# lilium_network register map
Vendor: Nordic Semiconductor; Series: nrfXX; File version: 1
CPU: CM33 r0p4, little endian, MPU, no FPU, 3 interrupt priority bits, 30 interrupts
Registers are 32-bit, read-write, reset 0x0 unless marked. A register's access mark holds for its fields unless they carry their own. Offsets are from the block's base; [hi:lo] are bit positions; {n}, {i} and the like mark numbered series; 'fields as' and 'values as' point back to an identical list.

## RADIO (part 1 of 3) — 2.4 GHz radio
Base 0x41008000
0x00 TASKS_TXEN wo — Enable RADIO in TX mode
  [0] TASKS_TXEN
    1=Trigger task
0x04 TASKS_RXEN wo — Enable RADIO in RX mode
  [0] TASKS_RXEN
    1=Trigger task
0x08 TASKS_START wo — Start RADIO
  [0] TASKS_START
    1=Trigger task
0x0C TASKS_STOP wo — Stop RADIO
  [0] TASKS_STOP
    1=Trigger task
0x10 TASKS_DISABLE wo — Disable RADIO
  [0] TASKS_DISABLE
    1=Trigger task
0x14 TASKS_RSSISTART wo — Start the RSSI and take one single sample of the receive signal strength
  [0] TASKS_RSSISTART
    1=Trigger task
0x18 TASKS_BCSTART wo — Start the bit counter
  [0] TASKS_BCSTART
    1=Trigger task
0x1C TASKS_BCSTOP wo — Stop the bit counter
  [0] TASKS_BCSTOP
    1=Trigger task
0x20 TASKS_EDSTART wo — Start the energy detect measurement used in IEEE 802.15.4 mode
  [0] TASKS_EDSTART
    1=Trigger task
0x24 TASKS_EDSTOP wo — Stop the energy detect measurement
  [0] TASKS_EDSTOP
    1=Trigger task
0x28 TASKS_CCASTART wo — Start the clear channel assessment used in IEEE 802.15.4 mode
  [0] TASKS_CCASTART
    1=Trigger task
0x2C TASKS_CCASTOP wo — Stop the clear channel assessment
  [0] TASKS_CCASTOP
    1=Trigger task
0x30 TASKS_DFESTART wo — Start DFE operation
  [0] TASKS_DFESTART
    1=Trigger task
0x34 TASKS_DFESTOP wo — Stop DFE operation
  [0] TASKS_DFESTOP
    1=Trigger task
0x38 TASKS_ACQINJ0DMASTART wo — Start DMA transaction
  [0] TASKS_ACQINJ0DMASTART
    1=Trigger task
0x3C TASKS_ACQINJ0DMASTOP wo — Stop ongoing DMA transaction
  [0] TASKS_ACQINJ0DMASTOP
    1=Trigger task
0x40 TASKS_ACQINJ1DMASTART wo — Start DMA transaction
  [0] TASKS_ACQINJ1DMASTART
    1=Trigger task
0x44 TASKS_ACQINJ1DMASTOP wo — Stop ongoing DMA transaction
  [0] TASKS_ACQINJ1DMASTOP
    1=Trigger task
0x48 TASKS_CNTPSTART wo — Start packet counter
  [0] TASKS_CNTPSTART
    1=Trigger task
0x4C TASKS_CNTPSTOP wo — Stop packet counter
  [0] TASKS_CNTPSTOP
    1=Trigger task
0x50 TASKS_CNTPCLEAR wo — Clear packet counter
  [0] TASKS_CNTPCLEAR
    1=Trigger task
0x54 TASKS_LOOPBACKEN wo — Enable RADIO in LOOPBACK mode
  [0] TASKS_LOOPBACKEN
    1=Trigger task
0x58 TASKS_CALSTART wo — Start calibration
  [0] TASKS_CALSTART
    1=Trigger task
0x5C TASKS_CALSTOP wo — Stop calibration
  [0] TASKS_CALSTOP
    1=Trigger task
0x60 TASKS_PATESTSTART wo — Start PA test
  [0] TASKS_PATESTSTART
    1=Trigger task
0x64 TASKS_PATESTSTOP wo — Stop PA test
  [0] TASKS_PATESTSTOP
    1=Trigger task
0x68 TASKS_CHNOINCR wo — Update RADIO channel based on the current channel and increment it according to chNoIncrStep
  [0] TASKS_CHNOINCR
    1=Trigger task
0x6C TASKS_DMASTART wo — Start RADIO DMA transaction
  [0] TASKS_DMASTART
    1=Trigger task
0x70 TASKS_DMASTOP wo — Stop ongoing RADIO DMA transaction
  [0] TASKS_DMASTOP
    1=Trigger task
0x74 TASKS_DFEDMASTART wo — Start DFE DMA transaction
  [0] TASKS_DFEDMASTART
    1=Trigger task
0x78 TASKS_DFEDMASTOP wo — Stop ongoing DFE DMA transaction
  [0] TASKS_DFEDMASTOP
    1=Trigger task
0x7C TASKS_RELOADFREQ wo — Reload new frequency while radio PLL is active
  [0] TASKS_RELOADFREQ
    1=Trigger task
0x80 TASKS_GETNEXTDETECT wo — Pull the last item out of the detect FIFO
  [0] TASKS_GETNEXTDETECT
    1=Trigger task
0x84 TASKS_CLEARDETECTFIFO wo — Clear the detect FIFO
  [0] TASKS_CLEARDETECTFIFO
    1=Trigger task
0x88 TASKS_RESETDEMODCTRL wo — Sets all things back to original state in RxDemodCtrl
  [0] TASKS_RESETDEMODCTRL
    1=Trigger task
0x8C TASKS_DEMODCTRLSTARTTIMER wo — Start the built-in custom timer (when starting the timer, it always starts from 0)
  [0] TASKS_DEMODCTRLSTARTTIMER
    1=Trigger task
0x90 TASKS_DEMODCTRLSTOPTIMER wo — Stop the built-in custom timer (when stopping the timer, it is always cleared afterwards)
  [0] TASKS_DEMODCTRLSTOPTIMER
    1=Trigger task
{0x94+4i} TASKS_DEMODCTRLCONDEN{i} wo (i=0..2) — Enable condition {i} (after this task has been triggered, the condition will trigger exactly once)
  [0] TASKS_DEMODCTRLCONDEN{i}
    1=Trigger task
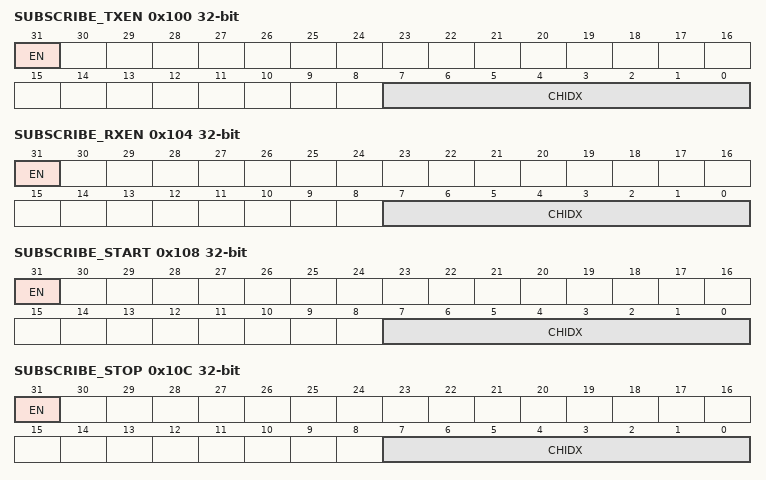
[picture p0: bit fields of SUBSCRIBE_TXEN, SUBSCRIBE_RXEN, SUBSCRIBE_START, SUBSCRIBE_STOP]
0x100 SUBSCRIBE_TXEN — Subscribe configuration for task TXEN
  [31] EN
    0=Disabled (Disable subscription); 1=Enabled (Enable subscription)
  [7:0] CHIDX — DPPI channel that task TXEN will subscribe to
0x104 SUBSCRIBE_RXEN — Subscribe configuration for task RXEN
  [31] EN
    values as SUBSCRIBE_TXEN.EN
  [7:0] CHIDX — DPPI channel that task RXEN will subscribe to
0x108 SUBSCRIBE_START — Subscribe configuration for task START
  [31] EN
    values as SUBSCRIBE_TXEN.EN
  [7:0] CHIDX — DPPI channel that task START will subscribe to
0x10C SUBSCRIBE_STOP — Subscribe configuration for task STOP
  [31] EN
    values as SUBSCRIBE_TXEN.EN
  [7:0] CHIDX — DPPI channel that task STOP will subscribe to
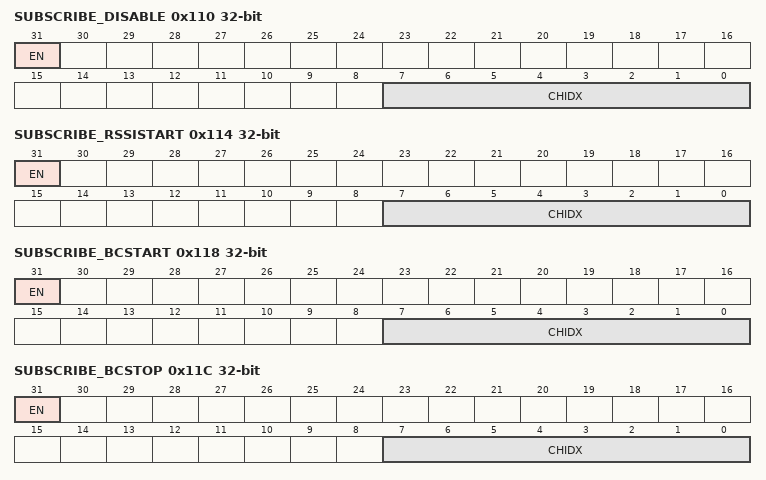
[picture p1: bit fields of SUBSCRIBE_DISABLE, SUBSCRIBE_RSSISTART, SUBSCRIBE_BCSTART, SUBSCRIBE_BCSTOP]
0x110 SUBSCRIBE_DISABLE — Subscribe configuration for task DISABLE
  [31] EN
    values as SUBSCRIBE_TXEN.EN
  [7:0] CHIDX — DPPI channel that task DISABLE will subscribe to
0x114 SUBSCRIBE_RSSISTART — Subscribe configuration for task RSSISTART
  [31] EN
    values as SUBSCRIBE_TXEN.EN
  [7:0] CHIDX — DPPI channel that task RSSISTART will subscribe to
0x118 SUBSCRIBE_BCSTART — Subscribe configuration for task BCSTART
  [31] EN
    values as SUBSCRIBE_TXEN.EN
  [7:0] CHIDX — DPPI channel that task BCSTART will subscribe to
0x11C SUBSCRIBE_BCSTOP — Subscribe configuration for task BCSTOP
  [31] EN
    values as SUBSCRIBE_TXEN.EN
  [7:0] CHIDX — DPPI channel that task BCSTOP will subscribe to
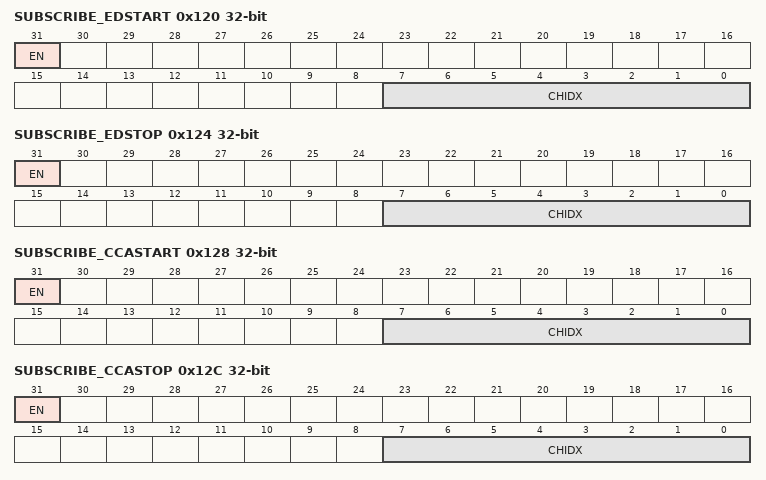
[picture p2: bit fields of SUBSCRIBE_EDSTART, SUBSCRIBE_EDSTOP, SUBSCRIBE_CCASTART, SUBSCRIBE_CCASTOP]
0x120 SUBSCRIBE_EDSTART — Subscribe configuration for task EDSTART
  [31] EN
    values as SUBSCRIBE_TXEN.EN
  [7:0] CHIDX — DPPI channel that task EDSTART will subscribe to
0x124 SUBSCRIBE_EDSTOP — Subscribe configuration for task EDSTOP
  [31] EN
    values as SUBSCRIBE_TXEN.EN
  [7:0] CHIDX — DPPI channel that task EDSTOP will subscribe to
0x128 SUBSCRIBE_CCASTART — Subscribe configuration for task CCASTART
  [31] EN
    values as SUBSCRIBE_TXEN.EN
  [7:0] CHIDX — DPPI channel that task CCASTART will subscribe to
0x12C SUBSCRIBE_CCASTOP — Subscribe configuration for task CCASTOP
  [31] EN
    values as SUBSCRIBE_TXEN.EN
  [7:0] CHIDX — DPPI channel that task CCASTOP will subscribe to
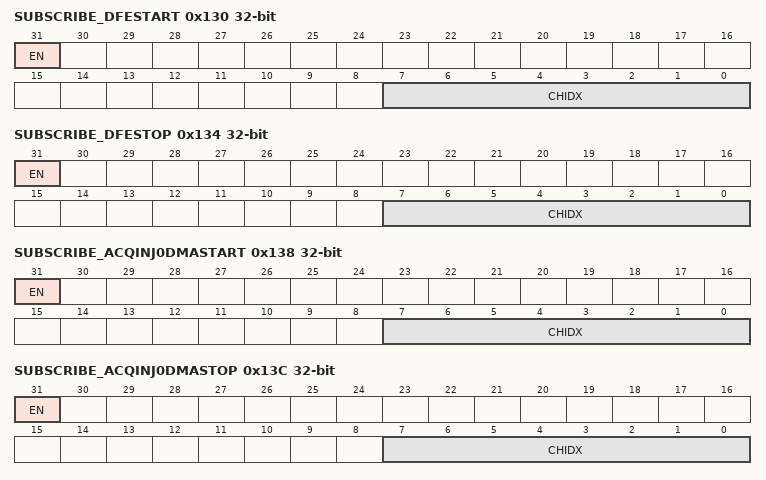
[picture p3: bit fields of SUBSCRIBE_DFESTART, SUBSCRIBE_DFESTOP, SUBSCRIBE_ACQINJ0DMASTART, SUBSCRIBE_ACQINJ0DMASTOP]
0x130 SUBSCRIBE_DFESTART — Subscribe configuration for task DFESTART
  [31] EN
    values as SUBSCRIBE_TXEN.EN
  [7:0] CHIDX — DPPI channel that task DFESTART will subscribe to
0x134 SUBSCRIBE_DFESTOP — Subscribe configuration for task DFESTOP
  [31] EN
    values as SUBSCRIBE_TXEN.EN
  [7:0] CHIDX — DPPI channel that task DFESTOP will subscribe to
0x138 SUBSCRIBE_ACQINJ0DMASTART — Subscribe configuration for task ACQINJ0DMASTART
  [31] EN
    values as SUBSCRIBE_TXEN.EN
  [7:0] CHIDX — DPPI channel that task ACQINJ0DMASTART will subscribe to
0x13C SUBSCRIBE_ACQINJ0DMASTOP — Subscribe configuration for task ACQINJ0DMASTOP
  [31] EN
    values as SUBSCRIBE_TXEN.EN
  [7:0] CHIDX — DPPI channel that task ACQINJ0DMASTOP will subscribe to
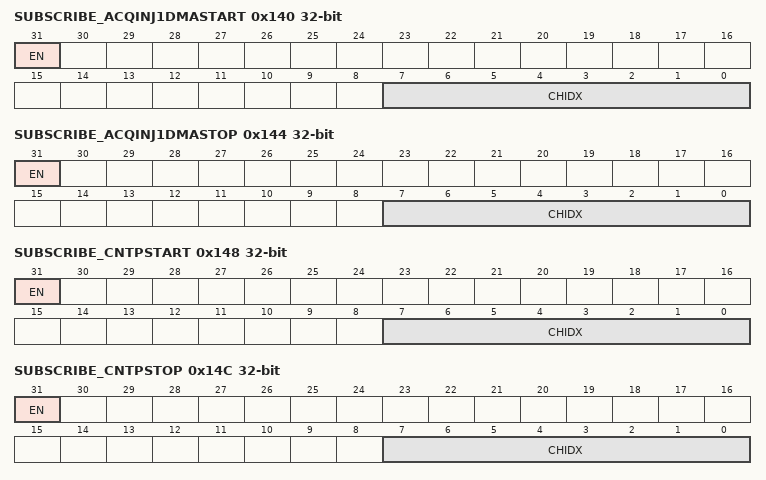
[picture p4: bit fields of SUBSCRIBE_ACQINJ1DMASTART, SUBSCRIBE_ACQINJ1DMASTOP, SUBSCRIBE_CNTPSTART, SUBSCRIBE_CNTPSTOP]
0x140 SUBSCRIBE_ACQINJ1DMASTART — Subscribe configuration for task ACQINJ1DMASTART
  [31] EN
    values as SUBSCRIBE_TXEN.EN
  [7:0] CHIDX — DPPI channel that task ACQINJ1DMASTART will subscribe to
0x144 SUBSCRIBE_ACQINJ1DMASTOP — Subscribe configuration for task ACQINJ1DMASTOP
  [31] EN
    values as SUBSCRIBE_TXEN.EN
  [7:0] CHIDX — DPPI channel that task ACQINJ1DMASTOP will subscribe to
0x148 SUBSCRIBE_CNTPSTART — Subscribe configuration for task CNTPSTART
  [31] EN
    values as SUBSCRIBE_TXEN.EN
  [7:0] CHIDX — DPPI channel that task CNTPSTART will subscribe to
0x14C SUBSCRIBE_CNTPSTOP — Subscribe configuration for task CNTPSTOP
  [31] EN
    values as SUBSCRIBE_TXEN.EN
  [7:0] CHIDX — DPPI channel that task CNTPSTOP will subscribe to
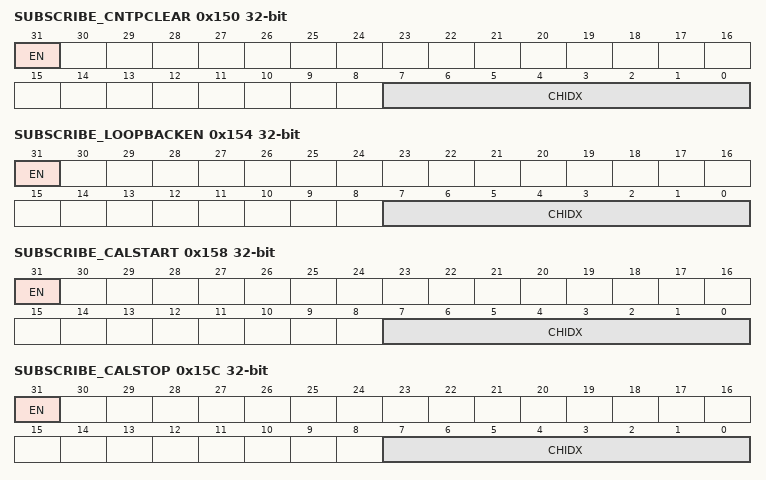
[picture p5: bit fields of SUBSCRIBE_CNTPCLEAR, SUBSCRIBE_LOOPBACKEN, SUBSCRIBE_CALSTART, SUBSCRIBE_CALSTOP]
0x150 SUBSCRIBE_CNTPCLEAR — Subscribe configuration for task CNTPCLEAR
  [31] EN
    values as SUBSCRIBE_TXEN.EN
  [7:0] CHIDX — DPPI channel that task CNTPCLEAR will subscribe to
0x154 SUBSCRIBE_LOOPBACKEN — Subscribe configuration for task LOOPBACKEN
  [31] EN
    values as SUBSCRIBE_TXEN.EN
  [7:0] CHIDX — DPPI channel that task LOOPBACKEN will subscribe to
0x158 SUBSCRIBE_CALSTART — Subscribe configuration for task CALSTART
  [31] EN
    values as SUBSCRIBE_TXEN.EN
  [7:0] CHIDX — DPPI channel that task CALSTART will subscribe to
0x15C SUBSCRIBE_CALSTOP — Subscribe configuration for task CALSTOP
  [31] EN
    values as SUBSCRIBE_TXEN.EN
  [7:0] CHIDX — DPPI channel that task CALSTOP will subscribe to
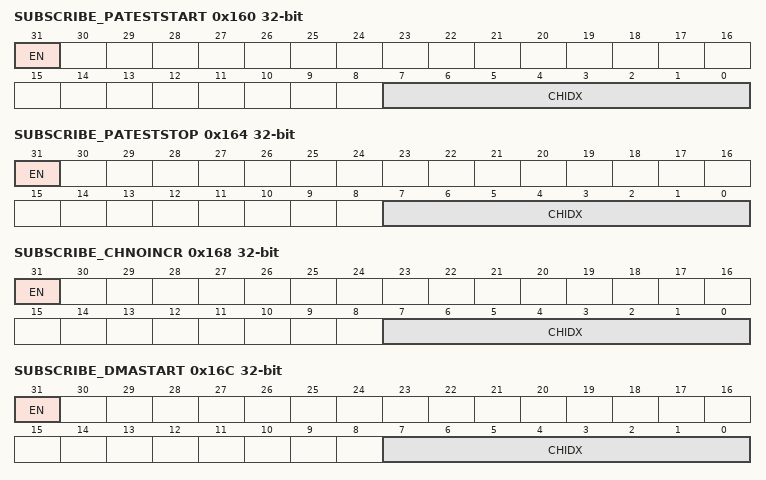
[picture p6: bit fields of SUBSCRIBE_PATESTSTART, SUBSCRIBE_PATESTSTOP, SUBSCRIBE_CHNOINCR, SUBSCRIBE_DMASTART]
0x160 SUBSCRIBE_PATESTSTART — Subscribe configuration for task PATESTSTART
  [31] EN
    values as SUBSCRIBE_TXEN.EN
  [7:0] CHIDX — DPPI channel that task PATESTSTART will subscribe to
0x164 SUBSCRIBE_PATESTSTOP — Subscribe configuration for task PATESTSTOP
  [31] EN
    values as SUBSCRIBE_TXEN.EN
  [7:0] CHIDX — DPPI channel that task PATESTSTOP will subscribe to
0x168 SUBSCRIBE_CHNOINCR — Subscribe configuration for task CHNOINCR
  [31] EN
    values as SUBSCRIBE_TXEN.EN
  [7:0] CHIDX — DPPI channel that task CHNOINCR will subscribe to
0x16C SUBSCRIBE_DMASTART — Subscribe configuration for task DMASTART
  [31] EN
    values as SUBSCRIBE_TXEN.EN
  [7:0] CHIDX — DPPI channel that task DMASTART will subscribe to
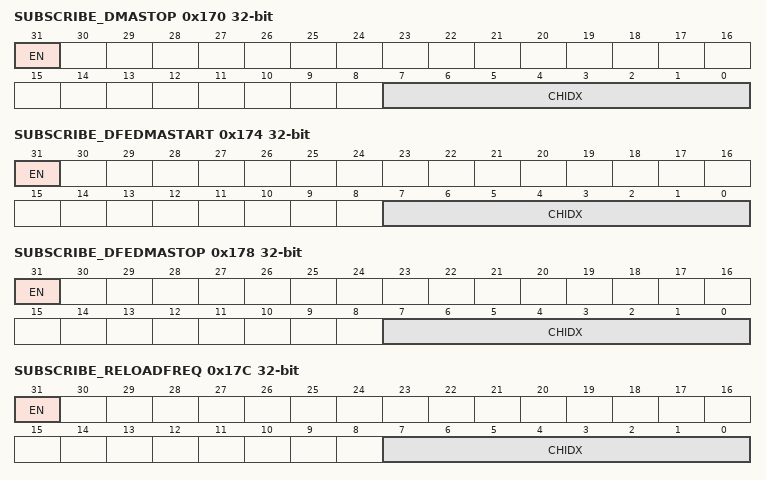
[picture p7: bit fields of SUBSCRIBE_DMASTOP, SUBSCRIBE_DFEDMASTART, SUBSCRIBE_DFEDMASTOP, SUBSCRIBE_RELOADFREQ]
0x170 SUBSCRIBE_DMASTOP — Subscribe configuration for task DMASTOP
  [31] EN
    values as SUBSCRIBE_TXEN.EN
  [7:0] CHIDX — DPPI channel that task DMASTOP will subscribe to
0x174 SUBSCRIBE_DFEDMASTART — Subscribe configuration for task DFEDMASTART
  [31] EN
    values as SUBSCRIBE_TXEN.EN
  [7:0] CHIDX — DPPI channel that task DFEDMASTART will subscribe to
0x178 SUBSCRIBE_DFEDMASTOP — Subscribe configuration for task DFEDMASTOP
  [31] EN
    values as SUBSCRIBE_TXEN.EN
  [7:0] CHIDX — DPPI channel that task DFEDMASTOP will subscribe to
0x17C SUBSCRIBE_RELOADFREQ — Subscribe configuration for task RELOADFREQ
  [31] EN
    values as SUBSCRIBE_TXEN.EN
  [7:0] CHIDX — DPPI channel that task RELOADFREQ will subscribe to
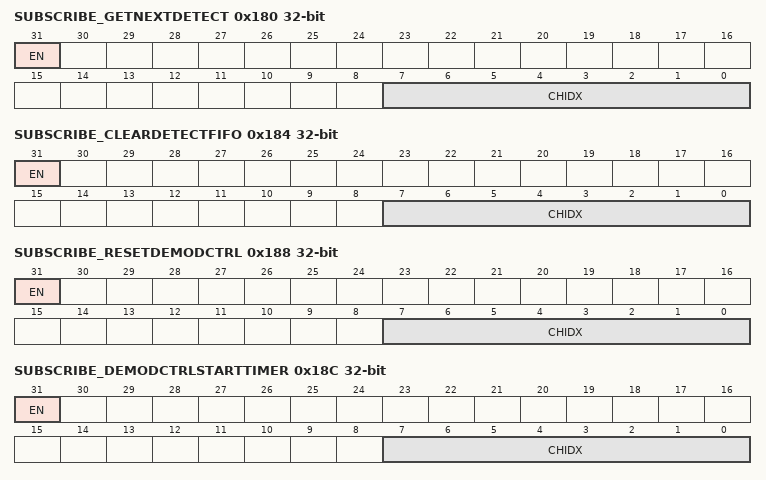
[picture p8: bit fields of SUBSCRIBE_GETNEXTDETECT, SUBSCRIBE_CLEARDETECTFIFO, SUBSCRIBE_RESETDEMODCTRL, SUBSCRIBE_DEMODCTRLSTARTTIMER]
0x180 SUBSCRIBE_GETNEXTDETECT — Subscribe configuration for task GETNEXTDETECT
  [31] EN
    values as SUBSCRIBE_TXEN.EN
  [7:0] CHIDX — DPPI channel that task GETNEXTDETECT will subscribe to
0x184 SUBSCRIBE_CLEARDETECTFIFO — Subscribe configuration for task CLEARDETECTFIFO
  [31] EN
    values as SUBSCRIBE_TXEN.EN
  [7:0] CHIDX — DPPI channel that task CLEARDETECTFIFO will subscribe to
0x188 SUBSCRIBE_RESETDEMODCTRL — Subscribe configuration for task RESETDEMODCTRL
  [31] EN
    values as SUBSCRIBE_TXEN.EN
  [7:0] CHIDX — DPPI channel that task RESETDEMODCTRL will subscribe to
0x18C SUBSCRIBE_DEMODCTRLSTARTTIMER — Subscribe configuration for task DEMODCTRLSTARTTIMER
  [31] EN
    values as SUBSCRIBE_TXEN.EN
  [7:0] CHIDX — DPPI channel that task DEMODCTRLSTARTTIMER will subscribe to
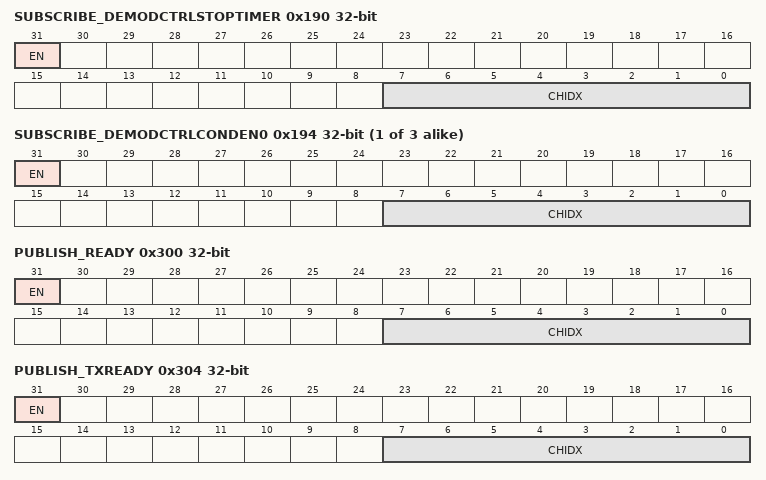
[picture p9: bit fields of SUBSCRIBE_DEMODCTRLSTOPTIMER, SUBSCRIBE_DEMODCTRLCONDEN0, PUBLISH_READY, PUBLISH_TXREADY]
0x190 SUBSCRIBE_DEMODCTRLSTOPTIMER — Subscribe configuration for task DEMODCTRLSTOPTIMER
  [31] EN
    values as SUBSCRIBE_TXEN.EN
  [7:0] CHIDX — DPPI channel that task DEMODCTRLSTOPTIMER will subscribe to
{0x194+4i} SUBSCRIBE_DEMODCTRLCONDEN{i} (i=0..2) — Subscribe configuration for task DEMODCTRLCONDEN{i}
  [31] EN
    values as SUBSCRIBE_TXEN.EN
  [7:0] CHIDX — DPPI channel that task DEMODCTRLCONDEN{i} will subscribe to
0x200 EVENTS_READY — RADIO has ramped up and is ready to be started
  [0] EVENTS_READY
    0=NotGenerated (Event not generated); 1=Generated (Event generated)
0x204 EVENTS_TXREADY — RADIO has ramped up and is ready to be started TX path
  [0] EVENTS_TXREADY
    values as EVENTS_READY.EVENTS_READY
0x208 EVENTS_RXREADY — RADIO has ramped up and is ready to be started RX path
  [0] EVENTS_RXREADY
    values as EVENTS_READY.EVENTS_READY
0x20C EVENTS_ADDRESS — Address sent or received
  [0] EVENTS_ADDRESS
    values as EVENTS_READY.EVENTS_READY
0x210 EVENTS_FRAMESTART — IEEE 802.15.4 length field received
  [0] EVENTS_FRAMESTART
    values as EVENTS_READY.EVENTS_READY
0x214 EVENTS_PAYLOAD — Packet payload sent or received
  [0] EVENTS_PAYLOAD
    values as EVENTS_READY.EVENTS_READY
0x218 EVENTS_END — Packet sent or received
  [0] EVENTS_END
    values as EVENTS_READY.EVENTS_READY
0x21C EVENTS_PHYEND — The last bit is sent on air or last bit is received
  [0] EVENTS_PHYEND
    values as EVENTS_READY.EVENTS_READY
0x220 EVENTS_DISABLED — RADIO has been disabled
  [0] EVENTS_DISABLED
    values as EVENTS_READY.EVENTS_READY
0x224 EVENTS_DEVMATCH — A device address match occurred on the last received packet
  [0] EVENTS_DEVMATCH
    values as EVENTS_READY.EVENTS_READY
0x228 EVENTS_DEVMISS — No device address match occurred on the last received packet
  [0] EVENTS_DEVMISS
    values as EVENTS_READY.EVENTS_READY
0x22C EVENTS_CRCOK — Packet received with CRC ok
  [0] EVENTS_CRCOK
    values as EVENTS_READY.EVENTS_READY
0x230 EVENTS_CRCERROR — Packet received with CRC error
  [0] EVENTS_CRCERROR
    values as EVENTS_READY.EVENTS_READY
0x238 EVENTS_BCMATCH — Bit counter reached bit count value
  [0] EVENTS_BCMATCH
    values as EVENTS_READY.EVENTS_READY
0x23C EVENTS_EDEND — Sampling of energy detection complete (a new ED sample is ready for readout from the RADIO.EDSAMPLE register)
  [0] EVENTS_EDEND
    values as EVENTS_READY.EVENTS_READY
0x240 EVENTS_EDSTOPPED — The sampling of energy detection has stopped
  [0] EVENTS_EDSTOPPED
    values as EVENTS_READY.EVENTS_READY
0x244 EVENTS_CCAIDLE — Wireless medium in idle - clear to send
  [0] EVENTS_CCAIDLE
    values as EVENTS_READY.EVENTS_READY
0x248 EVENTS_CCABUSY — Wireless medium busy - do not send
  [0] EVENTS_CCABUSY
    values as EVENTS_READY.EVENTS_READY
0x24C EVENTS_CCASTOPPED — The CCA has stopped
  [0] EVENTS_CCASTOPPED
    values as EVENTS_READY.EVENTS_READY
0x250 EVENTS_RATEBOOST — Ble_LR CI field received, receive mode is changed from Ble_LR125Kbit to Ble_LR500Kbit
  [0] EVENTS_RATEBOOST
    values as EVENTS_READY.EVENTS_READY
0x254 EVENTS_MHRMATCH — MAC header match found
  [0] EVENTS_MHRMATCH
    values as EVENTS_READY.EVENTS_READY
0x258 EVENTS_SYNC — Initial sync detected
  [0] EVENTS_SYNC
    values as EVENTS_READY.EVENTS_READY
0x25C EVENTS_CTEPRESENT — CTEInfo byte is received
  [0] EVENTS_CTEPRESENT
    values as EVENTS_READY.EVENTS_READY
0x260 EVENTS_CTEWARNING — CTEInfo byte received, but contain illegal CTETime or CTEType
  [0] EVENTS_CTEWARNING
    values as EVENTS_READY.EVENTS_READY
0x264 EVENTS_DFEEND — DFE operation has ended
  [0] EVENTS_DFEEND
    values as EVENTS_READY.EVENTS_READY
0x268 EVENTS_MODEWRITTEN — Generated on write access to MODE register
  [0] EVENTS_MODEWRITTEN
    values as EVENTS_READY.EVENTS_READY
0x26C EVENTS_MODEREADY — Generated immediately on write access to MODE register when MODEPROGENABLE==0, otherwise only manually triggered (SELECT_EVENTS_TRIGGERS=1)
  [0] EVENTS_MODEREADY
    values as EVENTS_READY.EVENTS_READY
0x270 EVENTS_CTEEND — CTE end
  [0] EVENTS_CTEEND
    values as EVENTS_READY.EVENTS_READY
0x274 EVENTS_LBREADY — RADIO is ready in loopback mode and is able to transmit and receive data
  [0] EVENTS_LBREADY
    values as EVENTS_READY.EVENTS_READY
0x278 EVENTS_CALDONE — RADIO calibration is done
  [0] EVENTS_CALDONE
    values as EVENTS_READY.EVENTS_READY
0x27C EVENTS_CHNOUPDATED — RADIO channel no. is updated
  [0] EVENTS_CHNOUPDATED
    values as EVENTS_READY.EVENTS_READY
0x280 EVENTS_DBCTIMEOUT — DBC timeout to be able to resync
  [0] EVENTS_DBCTIMEOUT
    values as EVENTS_READY.EVENTS_READY
0x284 EVENTS_TXTIMERMATCH — Tx timer match
  [0] EVENTS_TXTIMERMATCH
    values as EVENTS_READY.EVENTS_READY
0x288 EVENTS_RXTIMERMATCH — Rx timer match
  [0] EVENTS_RXTIMERMATCH
    values as EVENTS_READY.EVENTS_READY
0x290 EVENTS_RXDIGEN — RXDIGEN-signal was set high from the HW timing engine
  [0] EVENTS_RXDIGEN
    values as EVENTS_READY.EVENTS_READY
0x294 EVENTS_RAWDETECT — The double correlator detected one peak
  [0] EVENTS_RAWDETECT
    values as EVENTS_READY.EVENTS_READY
0x298 EVENTS_DETECTFIFOFULL — The detect FIFO is full (this should not happen if the FIFO is sized well enough)
  [0] EVENTS_DETECTFIFOFULL
    values as EVENTS_READY.EVENTS_READY
0x29C EVENTS_TIMERWRAPS — Event triggering when the timer wraps around (this is useful if one wants to count longer than the HW timer allows)
  [0] EVENTS_TIMERWRAPS
    values as EVENTS_READY.EVENTS_READY
0x2A0 EVENTS_STROBETIMETRACKUPDATED — New information from the symbol time tracker (see STROBETIMESTATUS)
  [0] EVENTS_STROBETIMETRACKUPDATED
    values as EVENTS_READY.EVENTS_READY
{0x2A4+4i} EVENTS_DEMODCTRLCONDTRIGGERED{i} (i=0..2) — Condition {i} triggered and actions done
  [0] EVENTS_DEMODCTRLCONDTRIGGERED{i}
    values as EVENTS_READY.EVENTS_READY
0x2B0 EVENTS_INTERCEPTEDTASK — A task has been intercepted (this event is non-interceptable)
  [0] EVENTS_INTERCEPTEDTASK
    values as EVENTS_READY.EVENTS_READY
0x2B4 EVENTS_INTERCEPTEDEVENT — An event has been intercepted (this event is non-interceptable)
  [0] EVENTS_INTERCEPTEDEVENT
    values as EVENTS_READY.EVENTS_READY
0x2C0 EVENTS_ACQINJ0DMAEND — ACQINJ0 DMA end
  [0] EVENTS_ACQINJ0DMAEND
    values as EVENTS_READY.EVENTS_READY
0x2C4 EVENTS_ACQINJ1DMAEND — ACQINJ1 DMA end
  [0] EVENTS_ACQINJ1DMAEND
    values as EVENTS_READY.EVENTS_READY
0x300 PUBLISH_READY — Publish configuration for event READY
  [31] EN
    0=Disabled (Disable publishing); 1=Enabled (Enable publishing)
  [7:0] CHIDX — DPPI channel that event READY will publish to
0x304 PUBLISH_TXREADY — Publish configuration for event TXREADY
  [31] EN
    values as PUBLISH_READY.EN
  [7:0] CHIDX — DPPI channel that event TXREADY will publish to
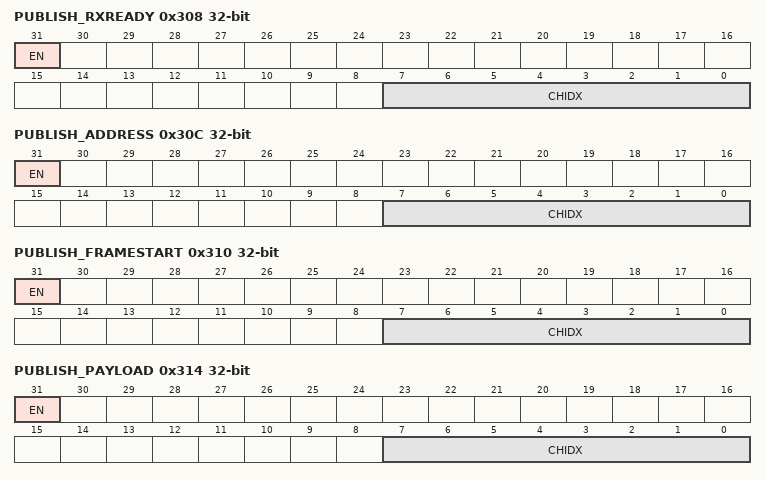
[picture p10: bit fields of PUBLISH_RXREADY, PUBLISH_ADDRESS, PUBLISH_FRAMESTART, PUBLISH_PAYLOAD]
0x308 PUBLISH_RXREADY — Publish configuration for event RXREADY
  [31] EN
    values as PUBLISH_READY.EN
  [7:0] CHIDX — DPPI channel that event RXREADY will publish to
0x30C PUBLISH_ADDRESS — Publish configuration for event ADDRESS
  [31] EN
    values as PUBLISH_READY.EN
  [7:0] CHIDX — DPPI channel that event ADDRESS will publish to
0x310 PUBLISH_FRAMESTART — Publish configuration for event FRAMESTART
  [31] EN
    values as PUBLISH_READY.EN
  [7:0] CHIDX — DPPI channel that event FRAMESTART will publish to
0x314 PUBLISH_PAYLOAD — Publish configuration for event PAYLOAD
  [31] EN
    values as PUBLISH_READY.EN
  [7:0] CHIDX — DPPI channel that event PAYLOAD will publish to
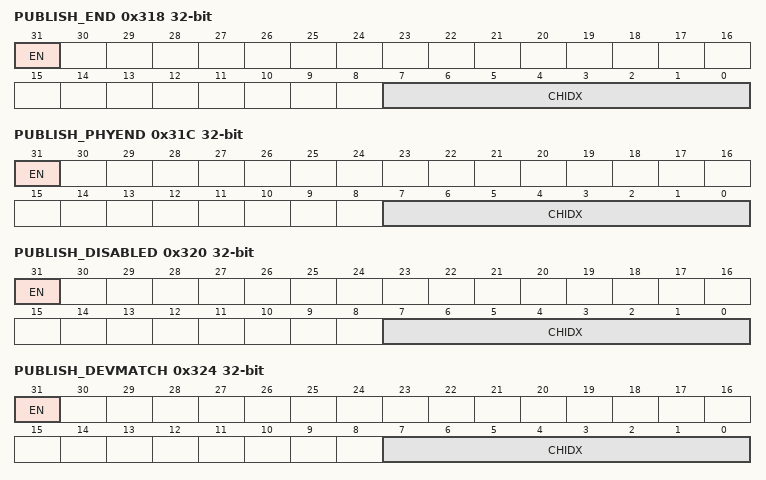
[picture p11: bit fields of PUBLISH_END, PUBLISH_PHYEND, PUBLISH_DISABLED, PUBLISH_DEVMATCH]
0x318 PUBLISH_END — Publish configuration for event END
  [31] EN
    values as PUBLISH_READY.EN
  [7:0] CHIDX — DPPI channel that event END will publish to
0x31C PUBLISH_PHYEND — Publish configuration for event PHYEND
  [31] EN
    values as PUBLISH_READY.EN
  [7:0] CHIDX — DPPI channel that event PHYEND will publish to
0x320 PUBLISH_DISABLED — Publish configuration for event DISABLED
  [31] EN
    values as PUBLISH_READY.EN
  [7:0] CHIDX — DPPI channel that event DISABLED will publish to
0x324 PUBLISH_DEVMATCH — Publish configuration for event DEVMATCH
  [31] EN
    values as PUBLISH_READY.EN
  [7:0] CHIDX — DPPI channel that event DEVMATCH will publish to
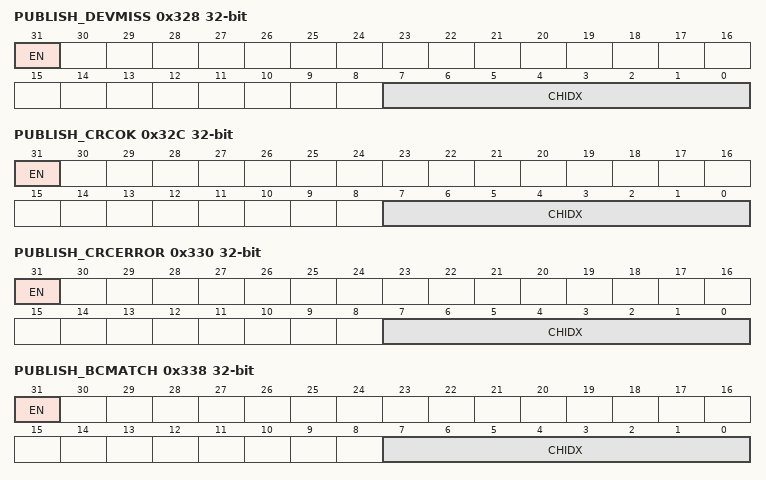
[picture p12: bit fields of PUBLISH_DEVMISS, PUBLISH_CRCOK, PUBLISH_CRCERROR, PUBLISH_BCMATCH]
0x328 PUBLISH_DEVMISS — Publish configuration for event DEVMISS
  [31] EN
    values as PUBLISH_READY.EN
  [7:0] CHIDX — DPPI channel that event DEVMISS will publish to
0x32C PUBLISH_CRCOK — Publish configuration for event CRCOK
  [31] EN
    values as PUBLISH_READY.EN
  [7:0] CHIDX — DPPI channel that event CRCOK will publish to
0x330 PUBLISH_CRCERROR — Publish configuration for event CRCERROR
  [31] EN
    values as PUBLISH_READY.EN
  [7:0] CHIDX — DPPI channel that event CRCERROR will publish to
0x338 PUBLISH_BCMATCH — Publish configuration for event BCMATCH
  [31] EN
    values as PUBLISH_READY.EN
  [7:0] CHIDX — DPPI channel that event BCMATCH will publish to
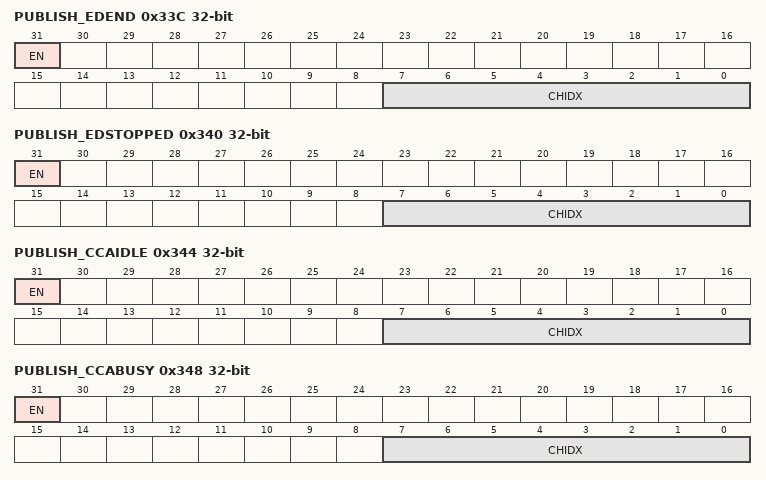
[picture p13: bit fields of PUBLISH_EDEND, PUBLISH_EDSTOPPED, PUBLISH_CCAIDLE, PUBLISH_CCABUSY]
0x33C PUBLISH_EDEND — Publish configuration for event EDEND
  [31] EN
    values as PUBLISH_READY.EN
  [7:0] CHIDX — DPPI channel that event EDEND will publish to
0x340 PUBLISH_EDSTOPPED — Publish configuration for event EDSTOPPED
  [31] EN
    values as PUBLISH_READY.EN
  [7:0] CHIDX — DPPI channel that event EDSTOPPED will publish to
0x344 PUBLISH_CCAIDLE — Publish configuration for event CCAIDLE
  [31] EN
    values as PUBLISH_READY.EN
  [7:0] CHIDX — DPPI channel that event CCAIDLE will publish to
0x348 PUBLISH_CCABUSY — Publish configuration for event CCABUSY
  [31] EN
    values as PUBLISH_READY.EN
  [7:0] CHIDX — DPPI channel that event CCABUSY will publish to
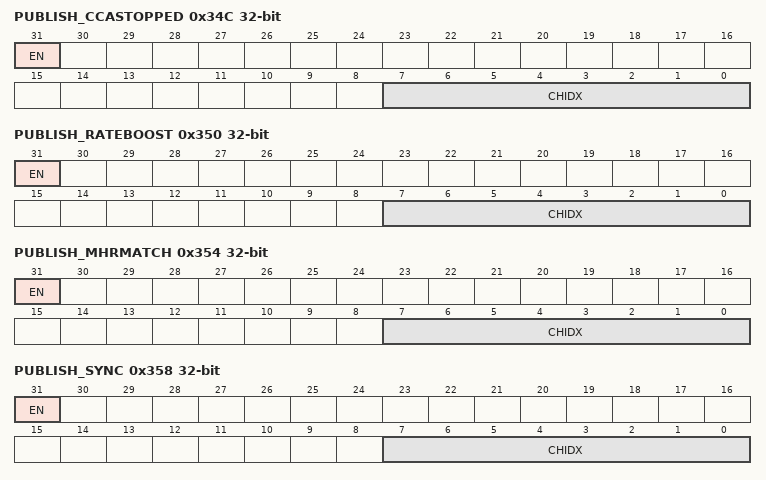
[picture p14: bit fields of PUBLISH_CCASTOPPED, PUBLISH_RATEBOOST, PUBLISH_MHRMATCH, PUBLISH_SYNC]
0x34C PUBLISH_CCASTOPPED — Publish configuration for event CCASTOPPED
  [31] EN
    values as PUBLISH_READY.EN
  [7:0] CHIDX — DPPI channel that event CCASTOPPED will publish to
0x350 PUBLISH_RATEBOOST — Publish configuration for event RATEBOOST
  [31] EN
    values as PUBLISH_READY.EN
  [7:0] CHIDX — DPPI channel that event RATEBOOST will publish to
0x354 PUBLISH_MHRMATCH — Publish configuration for event MHRMATCH
  [31] EN
    values as PUBLISH_READY.EN
  [7:0] CHIDX — DPPI channel that event MHRMATCH will publish to
0x358 PUBLISH_SYNC — Publish configuration for event SYNC
  [31] EN
    values as PUBLISH_READY.EN
  [7:0] CHIDX — DPPI channel that event SYNC will publish to
0x35C PUBLISH_CTEPRESENT — Publish configuration for event CTEPRESENT
  [31] EN
    values as PUBLISH_READY.EN
  [7:0] CHIDX — DPPI channel that event CTEPRESENT will publish to
0x360 PUBLISH_CTEWARNING — Publish configuration for event CTEWARNING
  [31] EN
    values as PUBLISH_READY.EN
  [7:0] CHIDX — DPPI channel that event CTEWARNING will publish to
0x364 PUBLISH_DFEEND — Publish configuration for event DFEEND
  [31] EN
    values as PUBLISH_READY.EN
  [7:0] CHIDX — DPPI channel that event DFEEND will publish to
0x368 PUBLISH_MODEWRITTEN — Publish configuration for event MODEWRITTEN
  [31] EN
    values as PUBLISH_READY.EN
  [7:0] CHIDX — DPPI channel that event MODEWRITTEN will publish to
0x36C PUBLISH_MODEREADY — Publish configuration for event MODEREADY
  [31] EN
    values as PUBLISH_READY.EN
  [7:0] CHIDX — DPPI channel that event MODEREADY will publish to
0x370 PUBLISH_CTEEND — Publish configuration for event CTEEND
  [31] EN
    values as PUBLISH_READY.EN
  [7:0] CHIDX — DPPI channel that event CTEEND will publish to
0x374 PUBLISH_LBREADY — Publish configuration for event LBREADY
  [31] EN
    values as PUBLISH_READY.EN
  [7:0] CHIDX — DPPI channel that event LBREADY will publish to
0x378 PUBLISH_CALDONE — Publish configuration for event CALDONE
  [31] EN
    values as PUBLISH_READY.EN
  [7:0] CHIDX — DPPI channel that event CALDONE will publish to
0x37C PUBLISH_CHNOUPDATED — Publish configuration for event CHNOUPDATED
  [31] EN
    values as PUBLISH_READY.EN
  [7:0] CHIDX — DPPI channel that event CHNOUPDATED will publish to
0x380 PUBLISH_DBCTIMEOUT — Publish configuration for event DBCTIMEOUT
  [31] EN
    values as PUBLISH_READY.EN
  [7:0] CHIDX — DPPI channel that event DBCTIMEOUT will publish to
0x384 PUBLISH_TXTIMERMATCH — Publish configuration for event TXTIMERMATCH
  [31] EN
    values as PUBLISH_READY.EN
  [7:0] CHIDX — DPPI channel that event TXTIMERMATCH will publish to
0x388 PUBLISH_RXTIMERMATCH — Publish configuration for event RXTIMERMATCH
  [31] EN
    values as PUBLISH_READY.EN
  [7:0] CHIDX — DPPI channel that event RXTIMERMATCH will publish to
0x390 PUBLISH_RXDIGEN — Publish configuration for event RXDIGEN
  [31] EN
    values as PUBLISH_READY.EN
  [7:0] CHIDX — DPPI channel that event RXDIGEN will publish to
0x394 PUBLISH_RAWDETECT — Publish configuration for event RAWDETECT
  [31] EN
    values as PUBLISH_READY.EN
  [7:0] CHIDX — DPPI channel that event RAWDETECT will publish to
0x398 PUBLISH_DETECTFIFOFULL — Publish configuration for event DETECTFIFOFULL
  [31] EN
    values as PUBLISH_READY.EN
  [7:0] CHIDX — DPPI channel that event DETECTFIFOFULL will publish to
0x39C PUBLISH_TIMERWRAPS — Publish configuration for event TIMERWRAPS
  [31] EN
    values as PUBLISH_READY.EN
  [7:0] CHIDX — DPPI channel that event TIMERWRAPS will publish to
0x3A0 PUBLISH_STROBETIMETRACKUPDATED — Publish configuration for event STROBETIMETRACKUPDATED
  [31] EN
    values as PUBLISH_READY.EN
  [7:0] CHIDX — DPPI channel that event STROBETIMETRACKUPDATED will publish to
{0x3A4+4i} PUBLISH_DEMODCTRLCONDTRIGGERED{i} (i=0..2) — Publish configuration for event DEMODCTRLCONDTRIGGERED{i}
  [31] EN
    values as PUBLISH_READY.EN
  [7:0] CHIDX — DPPI channel that event DEMODCTRLCONDTRIGGERED{i} will publish to
0x3B0 PUBLISH_INTERCEPTEDTASK — Publish configuration for event INTERCEPTEDTASK
  [31] EN
    values as PUBLISH_READY.EN
  [7:0] CHIDX — DPPI channel that event INTERCEPTEDTASK will publish to
0x3B4 PUBLISH_INTERCEPTEDEVENT — Publish configuration for event INTERCEPTEDEVENT
  [31] EN
    values as PUBLISH_READY.EN
  [7:0] CHIDX — DPPI channel that event INTERCEPTEDEVENT will publish to
0x3C0 PUBLISH_ACQINJ0DMAEND — Publish configuration for event ACQINJ0DMAEND
  [31] EN
    values as PUBLISH_READY.EN
  [7:0] CHIDX — DPPI channel that event ACQINJ0DMAEND will publish to
0x3C4 PUBLISH_ACQINJ1DMAEND — Publish configuration for event ACQINJ1DMAEND
  [31] EN
    values as PUBLISH_READY.EN
  [7:0] CHIDX — DPPI channel that event ACQINJ1DMAEND will publish to
0x400 SHORTS — Shortcuts between local events and tasks
  [all] fields
    0=Disabled (Disable shortcut); 1=Enabled (Enable shortcut)
  [26] CHNOUPDATED_LOOPBACKEN — Shortcut between event CHNOUPDATED and task LOOPBACKEN
  [25] CHNOUPDATED_RXEN — Shortcut between event CHNOUPDATED and task RXEN
  [24] CHNOUPDATED_TXEN — Shortcut between event CHNOUPDATED and task TXEN
  [23] DISABLED_CHNOINCR — Shortcut between event DISABLED and task CHNOINCR
  [22] DISABLED_LOOPBACKEN — Shortcut between event DISABLED and task LOOPBACKEN
  [21] DFEEND_STOP — Shortcut between event DFEEND and task STOP
  [20] PHYEND_START — Shortcut between event PHYEND and task START
  [19] PHYEND_DISABLE — Shortcut between event PHYEND and task DISABLE
  [18] RXREADY_START — Shortcut between event RXREADY and task START
  [17] TXREADY_START — Shortcut between event TXREADY and task START
  [16] CCAIDLE_STOP — Shortcut between event CCAIDLE and task STOP
  [15] EDEND_DISABLE — Shortcut between event EDEND and task DISABLE
  [14] READY_EDSTART — Shortcut between event READY and task EDSTART
  [13] FRAMESTART_BCSTART — Shortcut between event FRAMESTART and task BCSTART
  [12] CCABUSY_DISABLE — Shortcut between event CCABUSY and task DISABLE
  [11] CCAIDLE_TXEN — Shortcut between event CCAIDLE and task TXEN
  [10] RXREADY_CCASTART — Shortcut between event RXREADY and task CCASTART
  [9] CTEEND_START — Shortcut between event CTEEND and task START
  [8] CTEEND_DISABLE — Shortcut between event CTEEND and task DISABLE
  [6] ADDRESS_BCSTART — Shortcut between event ADDRESS and task BCSTART
  [5] END_START — Shortcut between event END and task START
  [4] ADDRESS_RSSISTART — Shortcut between event ADDRESS and task RSSISTART
  [3] DISABLED_RXEN — Shortcut between event DISABLED and task RXEN
  [2] DISABLED_TXEN — Shortcut between event DISABLED and task TXEN
  [1] END_DISABLE — Shortcut between event END and task DISABLE
  [0] READY_START — Shortcut between event READY and task START
0x480 INTEN00 — Enable or disable interrupt
  [all] fields
    0=Disabled; 1=Enabled
  [31] CHNOUPDATED — Enable or disable interrupt for event CHNOUPDATED
  [30] CALDONE — Enable or disable interrupt for event CALDONE
  [29] LBREADY — Enable or disable interrupt for event LBREADY
  [28] CTEEND — Enable or disable interrupt for event CTEEND
  [27] MODEREADY — Enable or disable interrupt for event MODEREADY
  [26] MODEWRITTEN — Enable or disable interrupt for event MODEWRITTEN
  [25] DFEEND — Enable or disable interrupt for event DFEEND
  [24] CTEWARNING — Enable or disable interrupt for event CTEWARNING
  [23] CTEPRESENT — Enable or disable interrupt for event CTEPRESENT
  [22] SYNC — Enable or disable interrupt for event SYNC
  [21] MHRMATCH — Enable or disable interrupt for event MHRMATCH
  [20] RATEBOOST — Enable or disable interrupt for event RATEBOOST
  [19] CCASTOPPED — Enable or disable interrupt for event CCASTOPPED
  [18] CCABUSY — Enable or disable interrupt for event CCABUSY
  [17] CCAIDLE — Enable or disable interrupt for event CCAIDLE
  [16] EDSTOPPED — Enable or disable interrupt for event EDSTOPPED
  [15] EDEND — Enable or disable interrupt for event EDEND
  [14] BCMATCH — Enable or disable interrupt for event BCMATCH
  [12] CRCERROR — Enable or disable interrupt for event CRCERROR
  [11] CRCOK — Enable or disable interrupt for event CRCOK
  [10] DEVMISS — Enable or disable interrupt for event DEVMISS
  [9] DEVMATCH — Enable or disable interrupt for event DEVMATCH
  [8] DISABLED — Enable or disable interrupt for event DISABLED
  [7] PHYEND — Enable or disable interrupt for event PHYEND
  [6] END — Enable or disable interrupt for event END
  [5] PAYLOAD — Enable or disable interrupt for event PAYLOAD
  [4] FRAMESTART — Enable or disable interrupt for event FRAMESTART
  [3] ADDRESS — Enable or disable interrupt for event ADDRESS
  [2] RXREADY — Enable or disable interrupt for event RXREADY
  [1] TXREADY — Enable or disable interrupt for event TXREADY
  [0] READY — Enable or disable interrupt for event READY
0x484 INTEN01 — Enable or disable interrupt
  [all] fields
    0=Disabled; 1=Enabled
  [17] ACQINJ1DMAEND — Enable or disable interrupt for event ACQINJ1DMAEND
  [16] ACQINJ0DMAEND — Enable or disable interrupt for event ACQINJ0DMAEND
  [13] INTERCEPTEDEVENT — Enable or disable interrupt for event INTERCEPTEDEVENT
  [12] INTERCEPTEDTASK — Enable or disable interrupt for event INTERCEPTEDTASK
  [11] DEMODCTRLCONDTRIGGERED2 — Enable or disable interrupt for event DEMODCTRLCONDTRIGGERED2
  [10] DEMODCTRLCONDTRIGGERED1 — Enable or disable interrupt for event DEMODCTRLCONDTRIGGERED1
  [9] DEMODCTRLCONDTRIGGERED0 — Enable or disable interrupt for event DEMODCTRLCONDTRIGGERED0
  [8] STROBETIMETRACKUPDATED — Enable or disable interrupt for event STROBETIMETRACKUPDATED
  [7] TIMERWRAPS — Enable or disable interrupt for event TIMERWRAPS
  [6] DETECTFIFOFULL — Enable or disable interrupt for event DETECTFIFOFULL
  [5] RAWDETECT — Enable or disable interrupt for event RAWDETECT
  [4] RXDIGEN — Enable or disable interrupt for event RXDIGEN
  [2] RXTIMERMATCH — Enable or disable interrupt for event RXTIMERMATCH
  [1] TXTIMERMATCH — Enable or disable interrupt for event TXTIMERMATCH
  [0] DBCTIMEOUT — Enable or disable interrupt for event DBCTIMEOUT
0x488 INTENSET00 — Enable interrupt
  [all] fields
    on read: 0=Disabled (Read: Disabled); 1=Enabled (Read: Enabled) | on write: 1=Set (Enable)
  [31] CHNOUPDATED — Write '1' to enable interrupt for event CHNOUPDATED
  [30] CALDONE — Write '1' to enable interrupt for event CALDONE
  [29] LBREADY — Write '1' to enable interrupt for event LBREADY
  [28] CTEEND — Write '1' to enable interrupt for event CTEEND
  [27] MODEREADY — Write '1' to enable interrupt for event MODEREADY
  [26] MODEWRITTEN — Write '1' to enable interrupt for event MODEWRITTEN
  [25] DFEEND — Write '1' to enable interrupt for event DFEEND
  [24] CTEWARNING — Write '1' to enable interrupt for event CTEWARNING
  [23] CTEPRESENT — Write '1' to enable interrupt for event CTEPRESENT
  [22] SYNC — Write '1' to enable interrupt for event SYNC
  [21] MHRMATCH — Write '1' to enable interrupt for event MHRMATCH
  [20] RATEBOOST — Write '1' to enable interrupt for event RATEBOOST
  [19] CCASTOPPED — Write '1' to enable interrupt for event CCASTOPPED
  [18] CCABUSY — Write '1' to enable interrupt for event CCABUSY
  [17] CCAIDLE — Write '1' to enable interrupt for event CCAIDLE
  [16] EDSTOPPED — Write '1' to enable interrupt for event EDSTOPPED
  [15] EDEND — Write '1' to enable interrupt for event EDEND
  [14] BCMATCH — Write '1' to enable interrupt for event BCMATCH
  [12] CRCERROR — Write '1' to enable interrupt for event CRCERROR
  [11] CRCOK — Write '1' to enable interrupt for event CRCOK
  [10] DEVMISS — Write '1' to enable interrupt for event DEVMISS
  [9] DEVMATCH — Write '1' to enable interrupt for event DEVMATCH
  [8] DISABLED — Write '1' to enable interrupt for event DISABLED
  [7] PHYEND — Write '1' to enable interrupt for event PHYEND
  [6] END — Write '1' to enable interrupt for event END
  [5] PAYLOAD — Write '1' to enable interrupt for event PAYLOAD
  [4] FRAMESTART — Write '1' to enable interrupt for event FRAMESTART
  [3] ADDRESS — Write '1' to enable interrupt for event ADDRESS
  [2] RXREADY — Write '1' to enable interrupt for event RXREADY
  [1] TXREADY — Write '1' to enable interrupt for event TXREADY
  [0] READY — Write '1' to enable interrupt for event READY
0x48C INTENSET01 — Enable interrupt
  [all] fields
    values as the fields of INTENSET00
  [17] ACQINJ1DMAEND — Write '1' to enable interrupt for event ACQINJ1DMAEND
  [16] ACQINJ0DMAEND — Write '1' to enable interrupt for event ACQINJ0DMAEND
  [13] INTERCEPTEDEVENT — Write '1' to enable interrupt for event INTERCEPTEDEVENT
  [12] INTERCEPTEDTASK — Write '1' to enable interrupt for event INTERCEPTEDTASK
  [11] DEMODCTRLCONDTRIGGERED2 — Write '1' to enable interrupt for event DEMODCTRLCONDTRIGGERED2
  [10] DEMODCTRLCONDTRIGGERED1 — Write '1' to enable interrupt for event DEMODCTRLCONDTRIGGERED1
  [9] DEMODCTRLCONDTRIGGERED0 — Write '1' to enable interrupt for event DEMODCTRLCONDTRIGGERED0
  [8] STROBETIMETRACKUPDATED — Write '1' to enable interrupt for event STROBETIMETRACKUPDATED
  [7] TIMERWRAPS — Write '1' to enable interrupt for event TIMERWRAPS
  [6] DETECTFIFOFULL — Write '1' to enable interrupt for event DETECTFIFOFULL
  [5] RAWDETECT — Write '1' to enable interrupt for event RAWDETECT
  [4] RXDIGEN — Write '1' to enable interrupt for event RXDIGEN
  [2] RXTIMERMATCH — Write '1' to enable interrupt for event RXTIMERMATCH
  [1] TXTIMERMATCH — Write '1' to enable interrupt for event TXTIMERMATCH
  [0] DBCTIMEOUT — Write '1' to enable interrupt for event DBCTIMEOUT
0x490 INTENCLR00 — Disable interrupt
  [all] fields
    on read: 0=Disabled (Read: Disabled); 1=Enabled (Read: Enabled) | on write: 1=Clear (Disable)
  [31] CHNOUPDATED — Write '1' to disable interrupt for event CHNOUPDATED
  [30] CALDONE — Write '1' to disable interrupt for event CALDONE
  [29] LBREADY — Write '1' to disable interrupt for event LBREADY
  [28] CTEEND — Write '1' to disable interrupt for event CTEEND
  [27] MODEREADY — Write '1' to disable interrupt for event MODEREADY
  [26] MODEWRITTEN — Write '1' to disable interrupt for event MODEWRITTEN
  [25] DFEEND — Write '1' to disable interrupt for event DFEEND
  [24] CTEWARNING — Write '1' to disable interrupt for event CTEWARNING
  [23] CTEPRESENT — Write '1' to disable interrupt for event CTEPRESENT
  [22] SYNC — Write '1' to disable interrupt for event SYNC
  [21] MHRMATCH — Write '1' to disable interrupt for event MHRMATCH
  [20] RATEBOOST — Write '1' to disable interrupt for event RATEBOOST
  [19] CCASTOPPED — Write '1' to disable interrupt for event CCASTOPPED
  [18] CCABUSY — Write '1' to disable interrupt for event CCABUSY
  [17] CCAIDLE — Write '1' to disable interrupt for event CCAIDLE
  [16] EDSTOPPED — Write '1' to disable interrupt for event EDSTOPPED
  [15] EDEND — Write '1' to disable interrupt for event EDEND
  [14] BCMATCH — Write '1' to disable interrupt for event BCMATCH
  [12] CRCERROR — Write '1' to disable interrupt for event CRCERROR
  [11] CRCOK — Write '1' to disable interrupt for event CRCOK
  [10] DEVMISS — Write '1' to disable interrupt for event DEVMISS
  [9] DEVMATCH — Write '1' to disable interrupt for event DEVMATCH
  [8] DISABLED — Write '1' to disable interrupt for event DISABLED
  [7] PHYEND — Write '1' to disable interrupt for event PHYEND
  [6] END — Write '1' to disable interrupt for event END
  [5] PAYLOAD — Write '1' to disable interrupt for event PAYLOAD
  [4] FRAMESTART — Write '1' to disable interrupt for event FRAMESTART
  [3] ADDRESS — Write '1' to disable interrupt for event ADDRESS
  [2] RXREADY — Write '1' to disable interrupt for event RXREADY
  [1] TXREADY — Write '1' to disable interrupt for event TXREADY
  [0] READY — Write '1' to disable interrupt for event READY
0x494 INTENCLR01 — Disable interrupt
  [all] fields
    values as the fields of INTENCLR00
  [17] ACQINJ1DMAEND — Write '1' to disable interrupt for event ACQINJ1DMAEND
  [16] ACQINJ0DMAEND — Write '1' to disable interrupt for event ACQINJ0DMAEND
  [13] INTERCEPTEDEVENT — Write '1' to disable interrupt for event INTERCEPTEDEVENT
  [12] INTERCEPTEDTASK — Write '1' to disable interrupt for event INTERCEPTEDTASK
  [11] DEMODCTRLCONDTRIGGERED2 — Write '1' to disable interrupt for event DEMODCTRLCONDTRIGGERED2
  [10] DEMODCTRLCONDTRIGGERED1 — Write '1' to disable interrupt for event DEMODCTRLCONDTRIGGERED1
  [9] DEMODCTRLCONDTRIGGERED0 — Write '1' to disable interrupt for event DEMODCTRLCONDTRIGGERED0
  [8] STROBETIMETRACKUPDATED — Write '1' to disable interrupt for event STROBETIMETRACKUPDATED
  [7] TIMERWRAPS — Write '1' to disable interrupt for event TIMERWRAPS
  [6] DETECTFIFOFULL — Write '1' to disable interrupt for event DETECTFIFOFULL
  [5] RAWDETECT — Write '1' to disable interrupt for event RAWDETECT
  [4] RXDIGEN — Write '1' to disable interrupt for event RXDIGEN
  [2] RXTIMERMATCH — Write '1' to disable interrupt for event RXTIMERMATCH
  [1] TXTIMERMATCH — Write '1' to disable interrupt for event TXTIMERMATCH
  [0] DBCTIMEOUT — Write '1' to disable interrupt for event DBCTIMEOUT
0x498 INTPEND00 ro — Pending interrupts
  [all] fields
    on read: 0=NotPending (Read: Not pending); 1=Pending (Read: Pending)
  [31] CHNOUPDATED — Read pending status of interrupt for event CHNOUPDATED
  [30] CALDONE — Read pending status of interrupt for event CALDONE
  [29] LBREADY — Read pending status of interrupt for event LBREADY
  [28] CTEEND — Read pending status of interrupt for event CTEEND
  [27] MODEREADY — Read pending status of interrupt for event MODEREADY
  [26] MODEWRITTEN — Read pending status of interrupt for event MODEWRITTEN
  [25] DFEEND — Read pending status of interrupt for event DFEEND
  [24] CTEWARNING — Read pending status of interrupt for event CTEWARNING
  [23] CTEPRESENT — Read pending status of interrupt for event CTEPRESENT
  [22] SYNC — Read pending status of interrupt for event SYNC
  [21] MHRMATCH — Read pending status of interrupt for event MHRMATCH
  [20] RATEBOOST — Read pending status of interrupt for event RATEBOOST
  [19] CCASTOPPED — Read pending status of interrupt for event CCASTOPPED
  [18] CCABUSY — Read pending status of interrupt for event CCABUSY
  [17] CCAIDLE — Read pending status of interrupt for event CCAIDLE
  [16] EDSTOPPED — Read pending status of interrupt for event EDSTOPPED
  [15] EDEND — Read pending status of interrupt for event EDEND
  [14] BCMATCH — Read pending status of interrupt for event BCMATCH
  [12] CRCERROR — Read pending status of interrupt for event CRCERROR
  [11] CRCOK — Read pending status of interrupt for event CRCOK
  [10] DEVMISS — Read pending status of interrupt for event DEVMISS
  [9] DEVMATCH — Read pending status of interrupt for event DEVMATCH
  [8] DISABLED — Read pending status of interrupt for event DISABLED
  [7] PHYEND — Read pending status of interrupt for event PHYEND
  [6] END — Read pending status of interrupt for event END
  [5] PAYLOAD — Read pending status of interrupt for event PAYLOAD
  [4] FRAMESTART — Read pending status of interrupt for event FRAMESTART
  [3] ADDRESS — Read pending status of interrupt for event ADDRESS
  [2] RXREADY — Read pending status of interrupt for event RXREADY
  [1] TXREADY — Read pending status of interrupt for event TXREADY
  [0] READY — Read pending status of interrupt for event READY
0x49C INTPEND01 ro — Pending interrupts
  [all] fields
    values as the fields of INTPEND00
  [17] ACQINJ1DMAEND — Read pending status of interrupt for event ACQINJ1DMAEND
  [16] ACQINJ0DMAEND — Read pending status of interrupt for event ACQINJ0DMAEND
  [13] INTERCEPTEDEVENT — Read pending status of interrupt for event INTERCEPTEDEVENT
  [12] INTERCEPTEDTASK — Read pending status of interrupt for event INTERCEPTEDTASK
  [11] DEMODCTRLCONDTRIGGERED2 — Read pending status of interrupt for event DEMODCTRLCONDTRIGGERED2
  [10] DEMODCTRLCONDTRIGGERED1 — Read pending status of interrupt for event DEMODCTRLCONDTRIGGERED1
  [9] DEMODCTRLCONDTRIGGERED0 — Read pending status of interrupt for event DEMODCTRLCONDTRIGGERED0
  [8] STROBETIMETRACKUPDATED — Read pending status of interrupt for event STROBETIMETRACKUPDATED
  [7] TIMERWRAPS — Read pending status of interrupt for event TIMERWRAPS
  [6] DETECTFIFOFULL — Read pending status of interrupt for event DETECTFIFOFULL
  [5] RAWDETECT — Read pending status of interrupt for event RAWDETECT
  [4] RXDIGEN — Read pending status of interrupt for event RXDIGEN
  [2] RXTIMERMATCH — Read pending status of interrupt for event RXTIMERMATCH
  [1] TXTIMERMATCH — Read pending status of interrupt for event TXTIMERMATCH
  [0] DBCTIMEOUT — Read pending status of interrupt for event DBCTIMEOUT
0x4A0 INTEN10 — Enable or disable interrupt
  fields as INTEN00
0x4A4 INTEN11 — Enable or disable interrupt
  fields as INTEN01
0x4A8 INTENSET10 — Enable interrupt
  fields as INTENSET00
0x4AC INTENSET11 — Enable interrupt
  fields as INTENSET01
0x4B0 INTENCLR10 — Disable interrupt
  fields as INTENCLR00
0x4B4 INTENCLR11 — Disable interrupt
  fields as INTENCLR01
0x4B8 INTPEND10 ro — Pending interrupts
  fields as INTPEND00
0x4BC INTPEND11 ro — Pending interrupts
  fields as INTPEND01
0x500 MODE — Data rate and modulation
  [3:0] MODE — Radio data rate and modulation setting. The radio supports frequency-shift keying (FSK) modulation.
    0=Nrf_1Mbit (1 Mbps Nordic proprietary radio mode); 1=Nrf_2Mbit (2 Mbps Nordic proprietary radio mode); 2=Nrf_250Kbit (Deprecated enumerator - 250 kbps Nordic proprietary radio mode); 3=Ble_1Mbit (1 Mbps BLE); 4=Ble_2Mbit (2 Mbps BLE); 5=Ble_LR125Kbit (Long range 125 kbps TX, 125 kbps and 500 kbps RX); 6=Ble_LR500Kbit (Long range 500 kbps TX, 125 kbps and 500 kbps RX); 9=Nrf_4Mbit0_5 (4 Mbps Nordic proprietary radio mode (BT=0.5/h=0.5)); 10=Nrf_4Mbit0_25 (4 Mbps Nordic proprietary radio mode (BT=0.5/h=0.25)); 15=Ieee802154_250Kbit (IEEE 802.15.4-2006 250 kbps)
0x504 MODEINTERNAL — Internal mode setting, active only when MODEPROGENABLE==1
  [3:0] MODEINTERNAL — Radio data rate and modulation setting. Same definition as MODE.
0x508 MODEPROGENABLE — Switch that enables programmable modes
  [0] MODEPROGENABLE — Enable manual triggering of MODEREADY event and activate MODEINTERNAL register (ie. MODEINTERNAL overrides MODE register)
0x50C MODEDEPENDENTXPBTEST
  [31:0] VAL — 32 bits, only for testing mode dependency
